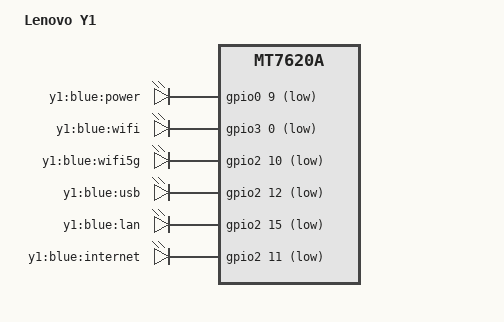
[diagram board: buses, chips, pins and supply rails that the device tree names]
/dts-v1/;

#include "Y1.dtsi"

/ {
	compatible = "lenovo,newifi-y1", "ralink,mt7620a-soc";
	model = "Lenovo Y1";

	aliases {
		led-boot = &led_power;
		led-failsafe = &led_power;
		led-running = &led_power;
		led-upgrade = &led_power;
	};

	leds {
		compatible = "gpio-leds";

		led_power: power {
			label = "y1:blue:power";
			gpios = <&gpio0 9 GPIO_ACTIVE_LOW>;
		};

		wlan1 {
			label = "y1:blue:wifi";
			gpios = <&gpio3 0 GPIO_ACTIVE_LOW>;
		};

		wlan2 {
			label = "y1:blue:wifi5g";
			gpios = <&gpio2 10 GPIO_ACTIVE_LOW>;
		};

		usb {
			label = "y1:blue:usb";
			gpios = <&gpio2 12 GPIO_ACTIVE_LOW>;
			trigger-sources = <&ohci_port1>, <&ehci_port1>;
			linux,default-trigger = "usbport";
		};

		lan {
			label = "y1:blue:lan";
			gpios = <&gpio2 15 GPIO_ACTIVE_LOW>;
		};

		internet {
			label = "y1:blue:internet";
			gpios = <&gpio2 11 GPIO_ACTIVE_LOW>;
		};
	};
};

&ethernet {
	pinctrl-names = "default";
	pinctrl-0 = <&ephy_pins>;
	mtd-mac-address = <&factory 0x4>;
	mediatek,portmap = "llllw";
};
